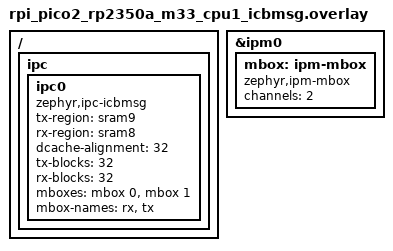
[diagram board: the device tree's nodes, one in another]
/*
 * Copyright (c) 2025 Dmitrii Sharshakov <d3dx12.xx@gmail.com>
 *
 * SPDX-License-Identifier: Apache-2.0
 */

&ipm0 {
	mbox: ipm-mbox {
		compatible = "zephyr,ipm-mbox";
		#mbox-cells = <1>;
		channels = <2>;
		status = "okay";
	};
};

/ {
	ipc {
		ipc0: ipc0 {
			compatible = "zephyr,ipc-icbmsg";
			tx-region = <&sram9>;
			rx-region = <&sram8>;
			dcache-alignment = <32>;
			tx-blocks = <32>;
			rx-blocks = <32>;
			mboxes = <&mbox 0>, <&mbox 1>;
			mbox-names = "rx", "tx";
			status = "okay";
		};
	};
};
